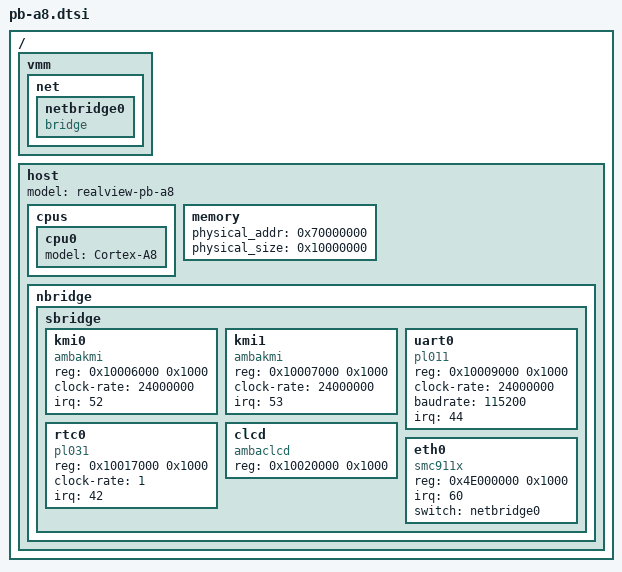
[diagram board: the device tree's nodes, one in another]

/ {
	vmm {
		net {
			netbridge0 {
				device_type = "netswitch";
				compatible = "bridge";
			};
		};
	};

	host {
		model = "realview-pb-a8";
		device_type = "host";
		
		cpus {
			cpu0 {
				device_type = "cpu";
				model = "Cortex-A8";
			};
		};

		memory {
			/* NOTE: By default QEMU will only proivde 128 MB 
			 * unless specified by "-m" option. If you have
			 * X MB then we will be able to access only first
			 * X MB starting at physical_addr.
			 */
			physical_addr = <0x70000000>;
			physical_size = <0x10000000>; /* 256 MB */
		};

		nbridge {
			sbridge {
				#address-cells = <1>;
				#size-cells = <1>;

				kmi0 { /* Keyboard */
			      		device_type = "serio";
			      		compatible = "ambakmi";
			      		reg = <0x10006000 0x1000>;
					clock-rate = <24000000>;
					irq = <52>;
				};

				kmi1 { /* Mouse */
			      		device_type = "serio";
			      		compatible = "ambakmi";
			      		reg = <0x10007000 0x1000>;
					clock-rate = <24000000>;
					irq = <53>;
				};

				uart0 {
			      		device_type = "serial";
			      		compatible = "pl011";
			      		reg = <0x10009000 0x1000>;
					clock-rate = <24000000>;
			      		baudrate = <115200>;
					irq = <44>;
				};

				rtc0 {
			      		device_type = "rtc";
			      		compatible = "pl031";
			      		reg = <0x10017000 0x1000>;
					clock-rate = <1>;
					irq = <42>;
				};

				clcd {
			      		device_type = "fb";
			      		compatible = "ambaclcd";
			      		reg = <0x10020000 0x1000>;
				};

				eth0 {
					device_type = "nic";
					compatible = "smc911x";
					reg = <0x4E000000 0x1000>;
					irq = <60>;
					switch = "netbridge0";
				};
			};
		};
	};
};
